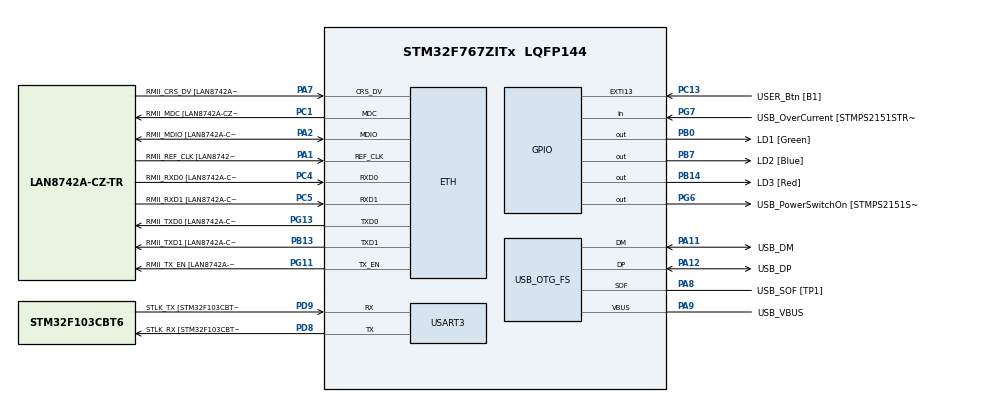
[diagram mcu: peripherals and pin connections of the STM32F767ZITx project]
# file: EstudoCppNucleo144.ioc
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ADC1.Channel-0\#ChannelRegularConversion=ADC_CHANNEL_TEMPSENSOR
ADC1.NbrOfConversionFlag=1
ADC1.Rank-0\#ChannelRegularConversion=1
ADC1.SamplingTime-0\#ChannelRegularConversion=ADC_SAMPLETIME_3CYCLES
ADC1.master=1
Dma.ADC1.2.Direction=DMA_PERIPH_TO_MEMORY
Dma.ADC1.2.FIFOMode=DMA_FIFOMODE_DISABLE
Dma.ADC1.2.Instance=DMA2_Stream0
Dma.ADC1.2.MemDataAlignment=DMA_MDATAALIGN_HALFWORD
Dma.ADC1.2.MemInc=DMA_MINC_ENABLE
Dma.ADC1.2.Mode=DMA_NORMAL
Dma.ADC1.2.PeriphDataAlignment=DMA_PDATAALIGN_HALFWORD
Dma.ADC1.2.PeriphInc=DMA_PINC_DISABLE
Dma.ADC1.2.Priority=DMA_PRIORITY_LOW
Dma.Request0=USART3_RX
Dma.Request1=USART3_TX
Dma.Request2=ADC1
Dma.USART3_RX.0.Direction=DMA_PERIPH_TO_MEMORY
Dma.USART3_RX.0.FIFOMode=DMA_FIFOMODE_DISABLE
Dma.USART3_RX.0.Instance=DMA1_Stream1
Dma.USART3_RX.0.MemDataAlignment=DMA_MDATAALIGN_BYTE
Dma.USART3_RX.0.MemInc=DMA_MINC_ENABLE
Dma.USART3_RX.0.Mode=DMA_NORMAL
Dma.USART3_RX.0.PeriphDataAlignment=DMA_PDATAALIGN_BYTE
Dma.USART3_RX.0.PeriphInc=DMA_PINC_DISABLE
Dma.USART3_RX.0.Priority=DMA_PRIORITY_LOW
Dma.USART3_TX.1.Direction=DMA_MEMORY_TO_PERIPH
Dma.USART3_TX.1.FIFOMode=DMA_FIFOMODE_DISABLE
Dma.USART3_TX.1.Instance=DMA1_Stream3
Dma.USART3_TX.1.MemDataAlignment=DMA_MDATAALIGN_BYTE
Dma.USART3_TX.1.MemInc=DMA_MINC_ENABLE
Dma.USART3_TX.1.Mode=DMA_NORMAL
Dma.USART3_TX.1.PeriphDataAlignment=DMA_PDATAALIGN_BYTE
Dma.USART3_TX.1.PeriphInc=DMA_PINC_DISABLE
Dma.USART3_TX.1.Priority=DMA_PRIORITY_LOW
ETH.MediaInterface=ETH_MEDIA_INTERFACE_RMII
ETH.PHY_Name=LAN8742A_PHY_ADDRESS
ETH.PHY_Value=0
ETH.PhyAddress=0
FREERTOS.Tasks01=defaultTask,0,128,StartDefaultTask,Default,NULL
Mcu.Family=STM32F7
Mcu.Name=STM32F767ZITx
Mcu.Package=LQFP144
NVIC.DMA1_Stream1_IRQn=true\:5\:0\:false\:false\:true\:true\:false\:true
NVIC.DMA1_Stream3_IRQn=true\:5\:0\:false\:false\:true\:true\:false\:true
NVIC.DMA2_Stream0_IRQn=true\:5\:0\:false\:false\:true\:true\:false\:true
NVIC.PriorityGroup=NVIC_PRIORITYGROUP_4
NVIC.TIM1_UP_TIM10_IRQn=true\:0\:0\:false\:false\:true\:false\:false\:true
NVIC.TimeBase=TIM1_UP_TIM10_IRQn
NVIC.TimeBaseIP=TIM1
PA1.GPIO_Label=RMII_REF_CLK [LAN8742A-CZ-TR_REFCLK0]
PA1.Mode=RMII
PA1.Signal=ETH_REF_CLK
PA10.GPIO_Label=USB_ID
PA10.Signal=USB_OTG_FS_ID
PA11.GPIO_Label=USB_DM
PA11.Mode=Device_Only
PA11.Signal=USB_OTG_FS_DM
PA12.GPIO_Label=USB_DP
PA12.Mode=Device_Only
PA12.Signal=USB_OTG_FS_DP
PA13.GPIO_Label=TMS
PA13.Mode=Serial_Wire
PA13.Signal=SYS_JTMS-SWDIO
PA14.GPIO_Label=TCK
PA14.Mode=Serial_Wire
PA14.Signal=SYS_JTCK-SWCLK
PA2.GPIO_Label=RMII_MDIO [LAN8742A-CZ-TR_MDIO]
PA2.Mode=RMII
PA2.Signal=ETH_MDIO
PA7.GPIO_Label=RMII_CRS_DV [LAN8742A-CZ-TR_CRS_DV]
PA7.Mode=RMII
PA7.Signal=ETH_CRS_DV
PA8.GPIO_Label=USB_SOF [TP1]
PA8.Mode=Activate_SOF_FS
PA8.Signal=USB_OTG_FS_SOF
PA9.GPIO_Label=USB_VBUS
PA9.Mode=Activate_VBUS
PA9.Signal=USB_OTG_FS_VBUS
PB0.GPIO_Label=LD1 [Green]
PB0.Signal=GPIO_Output
PB13.GPIO_Label=RMII_TXD1 [LAN8742A-CZ-TR_TXD1]
PB13.Mode=RMII
PB13.Signal=ETH_TXD1
PB14.GPIO_Label=LD3 [Red]
PB14.Signal=GPIO_Output
PB3.GPIO_Label=SWO
PB3.Signal=SYS_JTDO-SWO
PB7.GPIO_Label=LD2 [Blue]
PB7.Signal=GPIO_Output
PC1.GPIO_Label=RMII_MDC [LAN8742A-CZ-TR_MDC]
PC1.Mode=RMII
PC1.Signal=ETH_MDC
PC13.GPIO_Label=USER_Btn [B1]
PC13.Signal=GPXTI13
PC14/OSC32_IN.Mode=LSE-External-Oscillator
PC14/OSC32_IN.Signal=RCC_OSC32_IN
PC15/OSC32_OUT.Mode=LSE-External-Oscillator
PC15/OSC32_OUT.Signal=RCC_OSC32_OUT
PC4.GPIO_Label=RMII_RXD0 [LAN8742A-CZ-TR_RXD0]
PC4.Mode=RMII
PC4.Signal=ETH_RXD0
PC5.GPIO_Label=RMII_RXD1 [LAN8742A-CZ-TR_RXD1]
PC5.Mode=RMII
PC5.Signal=ETH_RXD1
PD8.GPIO_Label=STLK_RX [STM32F103CBT6_PA3]
PD8.Mode=Asynchronous
PD8.Signal=USART3_TX
PD9.GPIO_Label=STLK_TX [STM32F103CBT6_PA2]
PD9.Mode=Asynchronous
PD9.Signal=USART3_RX
PG11.GPIO_Label=RMII_TX_EN [LAN8742A-CZ-TR_TXEN]
PG11.Mode=RMII
PG11.Signal=ETH_TX_EN
PG13.GPIO_Label=RMII_TXD0 [LAN8742A-CZ-TR_TXD0]
PG13.Mode=RMII
PG13.Signal=ETH_TXD0
PG6.GPIO_Label=USB_PowerSwitchOn [STMPS2151STR_EN]
PG6.Signal=GPIO_Output
PG7.GPIO_Label=USB_OverCurrent [STMPS2151STR_FAULT]
PG7.Signal=GPIO_Input
PH0/OSC_IN.GPIO_Label=MCO [STM32F103CBT6_PA8]
PH0/OSC_IN.Mode=HSE-External-Clock-Source
PH0/OSC_IN.Signal=RCC_OSC_IN
PH1/OSC_OUT.Mode=HSE-External-Clock-Source
PH1/OSC_OUT.Signal=RCC_OSC_OUT
ProjectManager.HeapSize=0x200
ProjectManager.StackSize=0x400
ProjectManager.TargetToolchain=STM32CubeIDE
RCC.48MHZClocksFreq_Value=24000000
RCC.AHBFreq_Value=216000000
RCC.APB1CLKDivider=RCC_HCLK_DIV4
RCC.APB1Freq_Value=54000000
RCC.APB1TimFreq_Value=108000000
RCC.APB2CLKDivider=RCC_HCLK_DIV2
RCC.APB2Freq_Value=108000000
RCC.APB2TimFreq_Value=216000000
RCC.CortexFreq_Value=216000000
RCC.HCLKFreq_Value=216000000
RCC.HSE_VALUE=8000000
RCC.HSI_VALUE=16000000
RCC.PLLM=4
RCC.PLLMUL=RCC_PLL_MUL9
RCC.PLLN=216
RCC.PLLQ=9
RCC.PRESCALERUSB=RCC_USBCLKSOURCE_PLL_DIV1_5
RCC.SYSCLKFreq_VALUE=216000000
RCC.SYSCLKSource=RCC_SYSCLKSOURCE_PLLCLK
RCC.SYSCLKSourceVirtual=RCC_SYSCLKSOURCE_PLLCLK
RCC.USBFreq_Value=48000000
RCC.VCOOutputFreq_Value=432000000
USART3.VirtualMode-Asynchronous=VM_ASYNC
USB_OTG_FS.VirtualMode=Device_Only
VP_ADC1_TempSens_Input.Mode=IN-TempSens
VP_ADC1_Vref_Input.Mode=IN-Vrefint
VP_FREERTOS_VS_CMSIS_V1.Mode=CMSIS_V1
VP_SYS_VS_tim1.Mode=TIM1
board=NUCLEO-F767ZI

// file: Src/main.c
#include "main.h"
#include "cmsis_os.h"

ETH_HandleTypeDef heth;

PCD_HandleTypeDef hpcd_USB_OTG_FS;

osThreadId defaultTaskHandle;

void SystemClock_Config(void);
static void MX_GPIO_Init(void);
static void MX_DMA_Init(void);
static void MX_ETH_Init(void);
static void MX_USART3_UART_Init(void);
static void MX_USB_OTG_FS_PCD_Init(void);
static void MX_ADC1_Init(void);
void StartDefaultTask(void const * argument);

int main(void)
{
  HAL_Init();
  SystemClock_Config();

  MX_GPIO_Init();
  MX_DMA_Init();
  MX_ETH_Init();
  MX_USART3_UART_Init();
  MX_USB_OTG_FS_PCD_Init();
  MX_ADC1_Init();

  osThreadDef(defaultTask, StartDefaultTask, osPriorityNormal, 0, 128);
  defaultTaskHandle = osThreadCreate(osThread(defaultTask), NULL);

  /* Start scheduler */
  osKernelStart();

  /* We should never get here as control is now taken by the scheduler */

  /* Infinite loop */
  while (1)
  {

  }
}

void StartDefaultTask(void const * argument)
{
  /* USER CODE BEGIN 5 */
  /* Infinite loop */
  for(;;)
  {
	CppMain();

    osDelay(1);
  }
  /* USER CODE END 5 */
}

void SystemClock_Config(void)
{
  LL_FLASH_SetLatency(LL_FLASH_LATENCY_7);

  if(LL_FLASH_GetLatency() != LL_FLASH_LATENCY_7)
  {
  Error_Handler();
  }
  LL_PWR_SetRegulVoltageScaling(LL_PWR_REGU_VOLTAGE_SCALE1);
  LL_PWR_EnableOverDriveMode();
  LL_RCC_HSE_EnableBypass();
  LL_RCC_HSE_Enable();

   /* Wait till HSE is ready */
  while(LL_RCC_HSE_IsReady() != 1)
  {

  }
  LL_RCC_PLL_ConfigDomain_SYS(LL_RCC_PLLSOURCE_HSE, LL_RCC_PLLM_DIV_4, 216, LL_RCC_PLLP_DIV_2);
  LL_RCC_PLL_ConfigDomain_48M(LL_RCC_PLLSOURCE_HSE, LL_RCC_PLLM_DIV_4, 216, LL_RCC_PLLQ_DIV_9);
  LL_RCC_PLL_Enable();

   /* Wait till PLL is ready */
  while(LL_RCC_PLL_IsReady() != 1)
  {

  }
  LL_RCC_SetAHBPrescaler(LL_RCC_SYSCLK_DIV_1);
  LL_RCC_SetAPB1Prescaler(LL_RCC_APB1_DIV_4);
  LL_RCC_SetAPB2Prescaler(LL_RCC_APB2_DIV_2);
  LL_RCC_SetSysClkSource(LL_RCC_SYS_CLKSOURCE_PLL);

   /* Wait till System clock is ready */
  while(LL_RCC_GetSysClkSource() != LL_RCC_SYS_CLKSOURCE_STATUS_PLL)
  {

  }
  LL_SetSystemCoreClock(216000000);
  LL_RCC_SetUSBClockSource(LL_RCC_USB_CLKSOURCE_PLL);
  LL_RCC_SetUSARTClockSource(LL_RCC_USART3_CLKSOURCE_PCLK1);
}

static void MX_ADC1_Init(void)
{

  LL_ADC_InitTypeDef ADC_InitStruct = {0};
  LL_ADC_REG_InitTypeDef ADC_REG_InitStruct = {0};
  LL_ADC_CommonInitTypeDef ADC_CommonInitStruct = {0};

  /* Peripheral clock enable */
  LL_APB2_GRP1_EnableClock(LL_APB2_GRP1_PERIPH_ADC1);

  /* ADC1 DMA Init */

  /* ADC1 Init */
  LL_DMA_SetChannelSelection(DMA2, LL_DMA_STREAM_0, LL_DMA_CHANNEL_0);

  LL_DMA_SetDataTransferDirection(DMA2, LL_DMA_STREAM_0, LL_DMA_DIRECTION_PERIPH_TO_MEMORY);

  LL_DMA_SetStreamPriorityLevel(DMA2, LL_DMA_STREAM_0, LL_DMA_PRIORITY_LOW);

  LL_DMA_SetMode(DMA2, LL_DMA_STREAM_0, LL_DMA_MODE_NORMAL);

  LL_DMA_SetPeriphIncMode(DMA2, LL_DMA_STREAM_0, LL_DMA_PERIPH_NOINCREMENT);

  LL_DMA_SetMemoryIncMode(DMA2, LL_DMA_STREAM_0, LL_DMA_MEMORY_INCREMENT);

  LL_DMA_SetPeriphSize(DMA2, LL_DMA_STREAM_0, LL_DMA_PDATAALIGN_HALFWORD);

  LL_DMA_SetMemorySize(DMA2, LL_DMA_STREAM_0, LL_DMA_MDATAALIGN_HALFWORD);

  LL_DMA_DisableFifoMode(DMA2, LL_DMA_STREAM_0);

  /** Common config
  */
  ADC_InitStruct.Resolution = LL_ADC_RESOLUTION_12B;
  ADC_InitStruct.DataAlignment = LL_ADC_DATA_ALIGN_RIGHT;
  ADC_InitStruct.SequencersScanMode = LL_ADC_SEQ_SCAN_DISABLE;
  LL_ADC_Init(ADC1, &ADC_InitStruct);
  ADC_REG_InitStruct.TriggerSource = LL_ADC_REG_TRIG_SOFTWARE;
  ADC_REG_InitStruct.SequencerLength = LL_ADC_REG_SEQ_SCAN_DISABLE;
  ADC_REG_InitStruct.SequencerDiscont = LL_ADC_REG_SEQ_DISCONT_DISABLE;
  ADC_REG_InitStruct.ContinuousMode = LL_ADC_REG_CONV_SINGLE;
  ADC_REG_InitStruct.DMATransfer = LL_ADC_REG_DMA_TRANSFER_LIMITED;
  LL_ADC_REG_Init(ADC1, &ADC_REG_InitStruct);
  LL_ADC_REG_SetFlagEndOfConversion(ADC1, LL_ADC_REG_FLAG_EOC_UNITARY_CONV);
  LL_ADC_DisableIT_EOCS(ADC1);
  ADC_CommonInitStruct.CommonClock = LL_ADC_CLOCK_SYNC_PCLK_DIV4;
  ADC_CommonInitStruct.Multimode = LL_ADC_MULTI_INDEPENDENT;
  LL_ADC_CommonInit(__LL_ADC_COMMON_INSTANCE(ADC1), &ADC_CommonInitStruct);
  /** Configure Regular Channel
  */
  LL_ADC_REG_SetSequencerRanks(ADC1, LL_ADC_REG_RANK_1, LL_ADC_CHANNEL_TEMPSENSOR);
  LL_ADC_SetChannelSamplingTime(ADC1, LL_ADC_CHANNEL_TEMPSENSOR, LL_ADC_SAMPLINGTIME_3CYCLES);
  LL_ADC_SetCommonPathInternalCh(__LL_ADC_COMMON_INSTANCE(ADC1), LL_ADC_PATH_INTERNAL_TEMPSENSOR);

}

static void MX_ETH_Init(void)
{

   uint8_t MACAddr[6] ;

  heth.Instance = ETH;
  heth.Init.AutoNegotiation = ETH_AUTONEGOTIATION_ENABLE;
  heth.Init.PhyAddress = LAN8742A_PHY_ADDRESS;
  MACAddr[0] = 0x00;
  MACAddr[1] = 0x80;
  MACAddr[2] = 0xE1;
  MACAddr[3] = 0x00;
  MACAddr[4] = 0x00;
  MACAddr[5] = 0x00;
  heth.Init.MACAddr = &MACAddr[0];
  heth.Init.RxMode = ETH_RXPOLLING_MODE;
  heth.Init.ChecksumMode = ETH_CHECKSUM_BY_HARDWARE;
  heth.Init.MediaInterface = ETH_MEDIA_INTERFACE_RMII;

  if (HAL_ETH_Init(&heth) != HAL_OK)
  {
    Error_Handler();
  }

}

static void MX_USART3_UART_Init(void)
{

  LL_USART_InitTypeDef USART_InitStruct = {0};

  LL_GPIO_InitTypeDef GPIO_InitStruct = {0};

  /* Peripheral clock enable */
  LL_APB1_GRP1_EnableClock(LL_APB1_GRP1_PERIPH_USART3);

  LL_AHB1_GRP1_EnableClock(LL_AHB1_GRP1_PERIPH_GPIOD);
  /**USART3 GPIO Configuration
  PD8   ------> USART3_TX
  PD9   ------> USART3_RX
  */
  GPIO_InitStruct.Pin = STLK_RX_Pin;
  GPIO_InitStruct.Mode = LL_GPIO_MODE_ALTERNATE;
  GPIO_InitStruct.Speed = LL_GPIO_SPEED_FREQ_VERY_HIGH;
  GPIO_InitStruct.OutputType = LL_GPIO_OUTPUT_PUSHPULL;
  GPIO_InitStruct.Pull = LL_GPIO_PULL_NO;
  GPIO_InitStruct.Alternate = LL_GPIO_AF_7;
  LL_GPIO_Init(STLK_RX_GPIO_Port, &GPIO_InitStruct);

  GPIO_InitStruct.Pin = STLK_TX_Pin;
  GPIO_InitStruct.Mode = LL_GPIO_MODE_ALTERNATE;
  GPIO_InitStruct.Speed = LL_GPIO_SPEED_FREQ_VERY_HIGH;
  GPIO_InitStruct.OutputType = LL_GPIO_OUTPUT_PUSHPULL;
  GPIO_InitStruct.Pull = LL_GPIO_PULL_NO;
  GPIO_InitStruct.Alternate = LL_GPIO_AF_7;
  LL_GPIO_Init(STLK_TX_GPIO_Port, &GPIO_InitStruct);

  /* USART3 DMA Init */

  /* USART3_RX Init */
  LL_DMA_SetChannelSelection(DMA1, LL_DMA_STREAM_1, LL_DMA_CHANNEL_4);

  LL_DMA_SetDataTransferDirection(DMA1, LL_DMA_STREAM_1, LL_DMA_DIRECTION_PERIPH_TO_MEMORY);

  LL_DMA_SetStreamPriorityLevel(DMA1, LL_DMA_STREAM_1, LL_DMA_PRIORITY_LOW);

  LL_DMA_SetMode(DMA1, LL_DMA_STREAM_1, LL_DMA_MODE_NORMAL);

  LL_DMA_SetPeriphIncMode(DMA1, LL_DMA_STREAM_1, LL_DMA_PERIPH_NOINCREMENT);

  LL_DMA_SetMemoryIncMode(DMA1, LL_DMA_STREAM_1, LL_DMA_MEMORY_INCREMENT);

  LL_DMA_SetPeriphSize(DMA1, LL_DMA_STREAM_1, LL_DMA_PDATAALIGN_BYTE);

  LL_DMA_SetMemorySize(DMA1, LL_DMA_STREAM_1, LL_DMA_MDATAALIGN_BYTE);

  LL_DMA_DisableFifoMode(DMA1, LL_DMA_STREAM_1);

  /* USART3_TX Init */
  LL_DMA_SetChannelSelection(DMA1, LL_DMA_STREAM_3, LL_DMA_CHANNEL_4);

  LL_DMA_SetDataTransferDirection(DMA1, LL_DMA_STREAM_3, LL_DMA_DIRECTION_MEMORY_TO_PERIPH);

  LL_DMA_SetStreamPriorityLevel(DMA1, LL_DMA_STREAM_3, LL_DMA_PRIORITY_LOW);

  LL_DMA_SetMode(DMA1, LL_DMA_STREAM_3, LL_DMA_MODE_NORMAL);

  LL_DMA_SetPeriphIncMode(DMA1, LL_DMA_STREAM_3, LL_DMA_PERIPH_NOINCREMENT);

  LL_DMA_SetMemoryIncMode(DMA1, LL_DMA_STREAM_3, LL_DMA_MEMORY_INCREMENT);

  LL_DMA_SetPeriphSize(DMA1, LL_DMA_STREAM_3, LL_DMA_PDATAALIGN_BYTE);

  LL_DMA_SetMemorySize(DMA1, LL_DMA_STREAM_3, LL_DMA_MDATAALIGN_BYTE);

  LL_DMA_DisableFifoMode(DMA1, LL_DMA_STREAM_3);

  USART_InitStruct.BaudRate = 115200;
  USART_InitStruct.DataWidth = LL_USART_DATAWIDTH_8B;
  USART_InitStruct.StopBits = LL_USART_STOPBITS_1;
  USART_InitStruct.Parity = LL_USART_PARITY_NONE;
  USART_InitStruct.TransferDirection = LL_USART_DIRECTION_TX_RX;
  USART_InitStruct.HardwareFlowControl = LL_USART_HWCONTROL_NONE;
  USART_InitStruct.OverSampling = LL_USART_OVERSAMPLING_16;
  LL_USART_Init(USART3, &USART_InitStruct);
  LL_USART_ConfigAsyncMode(USART3);
  LL_USART_Enable(USART3);

}

static void MX_USB_OTG_FS_PCD_Init(void)
{

  hpcd_USB_OTG_FS.Instance = USB_OTG_FS;
  hpcd_USB_OTG_FS.Init.dev_endpoints = 6;
  hpcd_USB_OTG_FS.Init.speed = PCD_SPEED_FULL;
  hpcd_USB_OTG_FS.Init.dma_enable = DISABLE;
  hpcd_USB_OTG_FS.Init.phy_itface = PCD_PHY_EMBEDDED;
  hpcd_USB_OTG_FS.Init.Sof_enable = ENABLE;
  hpcd_USB_OTG_FS.Init.low_power_enable = DISABLE;
  hpcd_USB_OTG_FS.Init.lpm_enable = DISABLE;
  hpcd_USB_OTG_FS.Init.vbus_sensing_enable = ENABLE;
  hpcd_USB_OTG_FS.Init.use_dedicated_ep1 = DISABLE;
  if (HAL_PCD_Init(&hpcd_USB_OTG_FS) != HAL_OK)
  {
    Error_Handler();
  }

}

static void MX_DMA_Init(void)
{

  /* Init with LL driver */
  /* DMA controller clock enable */
  LL_AHB1_GRP1_EnableClock(LL_AHB1_GRP1_PERIPH_DMA1);
  LL_AHB1_GRP1_EnableClock(LL_AHB1_GRP1_PERIPH_DMA2);

  /* DMA interrupt init */
  /* DMA1_Stream1_IRQn interrupt configuration */
  NVIC_SetPriority(DMA1_Stream1_IRQn, NVIC_EncodePriority(NVIC_GetPriorityGrouping(),5, 0));
  NVIC_EnableIRQ(DMA1_Stream1_IRQn);
  /* DMA1_Stream3_IRQn interrupt configuration */
  NVIC_SetPriority(DMA1_Stream3_IRQn, NVIC_EncodePriority(NVIC_GetPriorityGrouping(),5, 0));
  NVIC_EnableIRQ(DMA1_Stream3_IRQn);
  /* DMA2_Stream0_IRQn interrupt configuration */
  NVIC_SetPriority(DMA2_Stream0_IRQn, NVIC_EncodePriority(NVIC_GetPriorityGrouping(),5, 0));
  NVIC_EnableIRQ(DMA2_Stream0_IRQn);

}

static void MX_GPIO_Init(void)
{
  LL_EXTI_InitTypeDef EXTI_InitStruct = {0};
  LL_GPIO_InitTypeDef GPIO_InitStruct = {0};

  /* GPIO Ports Clock Enable */
  LL_AHB1_GRP1_EnableClock(LL_AHB1_GRP1_PERIPH_GPIOC);
  LL_AHB1_GRP1_EnableClock(LL_AHB1_GRP1_PERIPH_GPIOH);
  LL_AHB1_GRP1_EnableClock(LL_AHB1_GRP1_PERIPH_GPIOA);
  LL_AHB1_GRP1_EnableClock(LL_AHB1_GRP1_PERIPH_GPIOB);
  LL_AHB1_GRP1_EnableClock(LL_AHB1_GRP1_PERIPH_GPIOD);
  LL_AHB1_GRP1_EnableClock(LL_AHB1_GRP1_PERIPH_GPIOG);

  /**/
  LL_GPIO_ResetOutputPin(LD1_GPIO_Port, LD1_Pin);

  /**/
  LL_GPIO_ResetOutputPin(LD3_GPIO_Port, LD3_Pin);

  /**/
  LL_GPIO_ResetOutputPin(USB_PowerSwitchOn_GPIO_Port, USB_PowerSwitchOn_Pin);

  /**/
  LL_GPIO_ResetOutputPin(LD2_GPIO_Port, LD2_Pin);

  /**/
  LL_SYSCFG_SetEXTISource(LL_SYSCFG_EXTI_PORTC, LL_SYSCFG_EXTI_LINE13);

  /**/
  EXTI_InitStruct.Line_0_31 = LL_EXTI_LINE_13;
  EXTI_InitStruct.LineCommand = ENABLE;
  EXTI_InitStruct.Mode = LL_EXTI_MODE_IT;
  EXTI_InitStruct.Trigger = LL_EXTI_TRIGGER_RISING;
  LL_EXTI_Init(&EXTI_InitStruct);

  /**/
  LL_GPIO_SetPinPull(USER_Btn_GPIO_Port, USER_Btn_Pin, LL_GPIO_PULL_NO);

  /**/
  LL_GPIO_SetPinMode(USER_Btn_GPIO_Port, USER_Btn_Pin, LL_GPIO_MODE_INPUT);

  /**/
  GPIO_InitStruct.Pin = LD1_Pin;
  GPIO_InitStruct.Mode = LL_GPIO_MODE_OUTPUT;
  GPIO_InitStruct.Speed = LL_GPIO_SPEED_FREQ_LOW;
  GPIO_InitStruct.OutputType = LL_GPIO_OUTPUT_PUSHPULL;
  GPIO_InitStruct.Pull = LL_GPIO_PULL_NO;
  LL_GPIO_Init(LD1_GPIO_Port, &GPIO_InitStruct);

  /**/
  GPIO_InitStruct.Pin = LD3_Pin;
  GPIO_InitStruct.Mode = LL_GPIO_MODE_OUTPUT;
  GPIO_InitStruct.Speed = LL_GPIO_SPEED_FREQ_LOW;
  GPIO_InitStruct.OutputType = LL_GPIO_OUTPUT_PUSHPULL;
  GPIO_InitStruct.Pull = LL_GPIO_PULL_NO;
  LL_GPIO_Init(LD3_GPIO_Port, &GPIO_InitStruct);

  /**/
  GPIO_InitStruct.Pin = USB_PowerSwitchOn_Pin;
  GPIO_InitStruct.Mode = LL_GPIO_MODE_OUTPUT;
  GPIO_InitStruct.Speed = LL_GPIO_SPEED_FREQ_LOW;
  GPIO_InitStruct.OutputType = LL_GPIO_OUTPUT_PUSHPULL;
  GPIO_InitStruct.Pull = LL_GPIO_PULL_NO;
  LL_GPIO_Init(USB_PowerSwitchOn_GPIO_Port, &GPIO_InitStruct);

  /**/
  GPIO_InitStruct.Pin = USB_OverCurrent_Pin;
  GPIO_InitStruct.Mode = LL_GPIO_MODE_INPUT;
  GPIO_InitStruct.Pull = LL_GPIO_PULL_NO;
  LL_GPIO_Init(USB_OverCurrent_GPIO_Port, &GPIO_InitStruct);

  /**/
  GPIO_InitStruct.Pin = LD2_Pin;
  GPIO_InitStruct.Mode = LL_GPIO_MODE_OUTPUT;
  GPIO_InitStruct.Speed = LL_GPIO_SPEED_FREQ_LOW;
  GPIO_InitStruct.OutputType = LL_GPIO_OUTPUT_PUSHPULL;
  GPIO_InitStruct.Pull = LL_GPIO_PULL_NO;
  LL_GPIO_Init(LD2_GPIO_Port, &GPIO_InitStruct);

}

void HAL_TIM_PeriodElapsedCallback(TIM_HandleTypeDef *htim)
{
  if (htim->Instance == TIM1) {
    HAL_IncTick();
  }
}

void Error_Handler(void)
{
}

/************************ (C) COPYRIGHT STMicroelectronics *****END OF FILE****/
